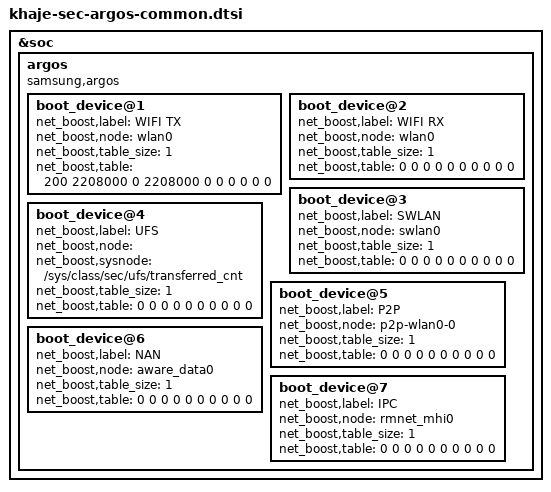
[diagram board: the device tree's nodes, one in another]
/* Copyright (c) 2016-2019, The Linux Foundation. All rights reserved.
 *
 * This program is free software; you can redistribute it and/or modify
 * it under the terms of the GNU General Public License version 2 and
 * only version 2 as published by the Free Software Foundation.
 *
 * This program is distributed in the hope that it will be useful,
 * but WITHOUT ANY WARRANTY; without even the implied warranty of
 * MERCHANTABILITY or FITNESS FOR A PARTICULAR PURPOSE.  See the
 * GNU General Public License for more details.
*/

&soc {
	argos {
		compatible = "samsung,argos";
		#address-cells = <1>;
		/* The device number should be assigned for each device, e.g. "boot_device@1" and "boot_device@2".
		 * Duplicated number is not allowed. Please refer the below example.
		 */
		/* Table Format should be
		 * <Throughput(Mbps) ARM_min ARM_max Little_min Little_max BIMC1 BIMC1 Task IRQ SCHED_boost>
		 * ARM_min : Big Core's minimum frequency lock. 0 means not set,
		 * ARM_max : Big Core's maximum frequency lock. 0 means not set,
		 * Little_min : Little Core's minimum frequency lock. 0 means not set,
		 * Little_max : Little Core's maximum frequency lock. 0 means not set,
		 * DDR clk : Memory frequency lock.
		 * reserved : reserved
		 * Task : 1 - Set task affinity lock.
		 *	0 - Not set or unlock,
		 *		Task affinity should be predefined driver's code.
		 * IRQ : 1 - Set irq affinity lock.
		 *       0 - Not set or unlock,
		 *		Task affinity should be predefined driver's code.
		 * SCHED_boost : 1 - Increase sched boosting count (not used now)
		 *             0 - Decrease sched boosting count
		 * net_boost,interval_idx : 0 - 1000ms interval
		 *                          1 - 500ms interval
		 *                          2 - 250ms interval
		 *                          interval_idx should be 0 or 1 or 2.
		 *                          default interval is 1000(ms), when
		 *                          boot_device@x doesn't have interval_idx
		 *                          node
		 */
		/*
		 *boot_device@1 {
		 *		net_boost,label="WIFI";
		 *		net_boost,node="wlan0";
		 *		net_boost,table_size = <4>;
		 *		net_boost,table= <
		 *			5  2016000 0 2016000 0 0 0 0 0 0
		 *			10  2016000 0 2016000 0 0 0 0 0 0
		 *			20  2016000 0 2016000 0 0 0 0 0 0
		 *			30  2016000 0 2016000 0 0 0 0 0 0
		 *			>;
		 *		net_boost,interval= <1>;
		 * };
		 */
		boot_device@1 {
			net_boost,label="WIFI TX";
			net_boost,node="wlan0";
			net_boost,table_size = <1>;
			net_boost,table= <
				200  2208000 0 2208000 0 0 0 0 0 0
				>;
		};
		boot_device@2 {
			net_boost,label="WIFI RX";
			net_boost,node="wlan0";
			net_boost,table_size = <1>;
			net_boost,table= <
				0 0 0 0 0 0 0 0 0 0
				>;
		};
		boot_device@3 {
			net_boost,label="SWLAN";
			net_boost,node="swlan0";
			net_boost,table_size = <1>;
			net_boost,table= <
				0 0 0 0 0 0 0 0 0 0
				>;
		};
		boot_device@4 {
			net_boost,label="UFS";
			net_boost,node="";
			net_boost,sysnode="/sys/class/sec/ufs/transferred_cnt";
			net_boost,table_size = <1>;
			net_boost,table= <
				0 0 0 0 0 0 0 0 0 0
				>;
			/* net_boost,interval_idx= <1>; */
		};
		boot_device@5 {
			net_boost,label="P2P";
			net_boost,node="p2p-wlan0-0";
			net_boost,table_size = <1>;
			net_boost,table= <
				0 0 0 0 0 0 0 0 0 0
				>;
		};
		boot_device@6 {
			net_boost,label="NAN";
			net_boost,node="aware_data0";
			net_boost,table_size = <1>;
			net_boost,table= <
				0 0 0 0 0 0 0 0 0 0
				>;
		};
		boot_device@7 {
			net_boost,label="IPC";
			/* net_boost,node="rmnet_data"; */
			net_boost,node="rmnet_mhi0";
			net_boost,table_size = <1>;
			net_boost,table= <
				0 0 0 0 0 0 0 0 0 0
				>;
		};
	};
};


